# MCXN947_cm33_core0 register map
Vendor: nxp.com; File version: 1.0
CPU: CM33 r2p0, little endian, MPU, FPU, VTOR, 3 interrupt priority bits
Registers are 32-bit, read-write, reset 0x0 unless marked. A register's access mark holds for its fields unless they carry their own. Offsets are from the block's base; [hi:lo] are bit positions; {n}, {i} and the like mark numbered series; 'fields as' and 'values as' point back to an identical list.

## FLEXIO0 — FLEXIO
Base 0x40105000
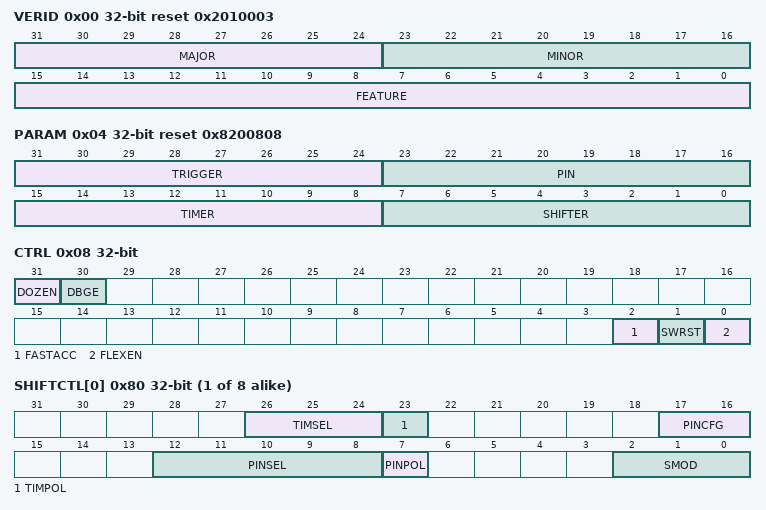
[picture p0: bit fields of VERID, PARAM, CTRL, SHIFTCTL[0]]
0x00 VERID ro reset 0x2010003 — Version ID Register
  [31:24] MAJOR — Major Version Number
  [23:16] MINOR — Minor Version Number
  [15:0] FEATURE — Feature Specification Number
    0=Standard features implemented; 1=state_logic_parallel (Supports state, logic, and parallel modes.); 2=pinctrl (Supports pin control registers.); 3=state_logic_parallel_pinctrl (Supports state, logic, and parallel modes, plus pin control registers.)
0x04 PARAM ro reset 0x8200808 — Parameter Register
  [31:24] TRIGGER — Trigger Number
  [23:16] PIN — Pin Number
  [15:8] TIMER — Timer Number
  [7:0] SHIFTER — Shifter Number
0x08 CTRL — FLEXIO Control Register
  [31] DOZEN — Doze Enable
    0=enable (FLEXIO enabled in Doze modes.); 1=disable (FLEXIO disabled in Doze modes.)
  [30] DBGE — Debug Enable
    0=disable (FLEXIO is disabled in Debug modes.); 1=emable (FLEXIO is enabled in Debug modes.)
  [2] FASTACC — Fast Access
    0=normal (Configures for normal register accesses to FLEXIO); 1=fast (Configures for fast register accesses to FLEXIO)
  [1] SWRST — Software Reset
    0=disable (Software reset is disabled); 1=enable (Software reset is enabled. All FLEXIO registers except the Control Register are reset.)
  [0] FLEXEN — FLEXIO Enable
    0=disable (FLEXIO module is disabled.); 1=enable (FLEXIO module is enabled.)
0x0C PIN ro — Pin State Register
  [31:0] PDI — Pin Data Input
0x10 SHIFTSTAT write-1-clears — Shifter Status Register
  [7:0] SSF write-1-clears — Shifter Status Flag
0x14 SHIFTERR write-1-clears — Shifter Error Register
  [7:0] SEF write-1-clears — Shifter Error Flags
0x18 TIMSTAT write-1-clears — Timer Status Register
  [7:0] TSF write-1-clears — Timer Status Flags
0x20 SHIFTSIEN — Shifter Status Interrupt Enable
  [7:0] SSIE
0x24 SHIFTEIEN — Shifter Error Interrupt Enable
  [7:0] SEIE
0x28 TIMIEN — Timer Interrupt Enable Register
  [7:0] TEIE — Timer Status Interrupt Enable
0x30 SHIFTSDEN — Shifter Status DMA Enable
  [7:0] SSDE
0x38 TIMERSDEN — Timer Status DMA Enable
  [7:0] TSDE
0x40 SHIFTSTATE — Shifter State Register
  [2:0] STATE — Current State Pointer
0x48 TRGSTAT write-1-clears — Trigger Status Register
  [7:0] ETSF write-1-clears — External Trigger Status Flags
0x4C TRIGIEN — External Trigger Interrupt Enable Register
  [7:0] TRIE — External Trigger Interrupt Enable
0x50 PINSTAT write-1-clears — Pin Status Register
  [31:0] PSF write-1-clears — Pin Status Flags
0x54 PINIEN — Pin Interrupt Enable Register
  [31:0] PSIE — Pin Status Interrupt Enable
0x58 PINREN — Pin Rising Edge Enable Register
  [31:0] PRE — Pin Rising Edge
0x5C PINFEN — Pin Falling Edge Enable Register
  [31:0] PFE — Pin Falling Edge
0x60 PINOUTD — Pin Output Data Register
  [31:0] OUTD — Output Data
0x64 PINOUTE — Pin Output Enable Register
  [31:0] OUTE — Output Enable
0x68 PINOUTDIS — Pin Output Disable Register
  [31:0] OUTDIS — Output Disable
0x6C PINOUTCLR — Pin Output Clear Register
  [31:0] OUTCLR — Output Clear
0x70 PINOUTSET — Pin Output Set Register
  [31:0] OUTSET — Output Set
0x74 PINOUTTOG — Pin Output Toggle Register
  [31:0] OUTTOG — Output Toggle
{0x80+4i} SHIFTCTL[{i}] (i=0..7) — Shifter Control N Register
  [26:24] TIMSEL — Timer Select
  [23] TIMPOL — Timer Polarity
    0=posedge (Shift on posedge of shift clock); 1=negedge (Shift on negedge of shift clock)
  [17:16] PINCFG — Shifter Pin Configuration
    0=disable (Shifter pin output disabled); 1=opend_bidirouten (Shifter pin open-drain or bidirectional output enable); 2=bidir_outdata (Shifter pin bidirectional output data); 3=output (Shifter pin output)
  [12:8] PINSEL — Shifter Pin Select
  [7] PINPOL — Shifter Pin Polarity
    0=active_high (Pin is active high); 1=active_low (Pin is active low)
  [2:0] SMOD — Shifter Mode
    0=Disabled; 1=Receive mode. Captures the current shifter content into the SHIFTBUF on expiration of the timer.; 2=Transmit mode. Load SHIFTBUF contents into the shifter on expiration of the timer.; 4=Match Store mode. Shifter data is compared to SHIFTBUF content on expiration of the timer.; 5=Match Continuous mode. Shifter data is continuously compared to SHIFTBUF contents.; 6=State mode. SHIFTBUF contents are used for storing programmable state attributes.; 7=Logic mode. SHIFTBUF contents are used for implementing programmable logic lookup table.
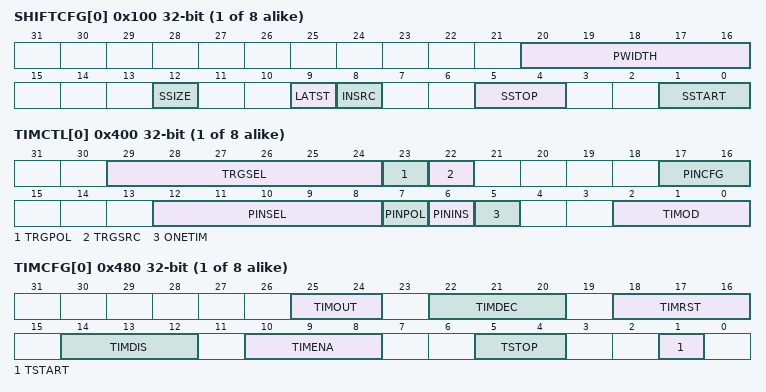
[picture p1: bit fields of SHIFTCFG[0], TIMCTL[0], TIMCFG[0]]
{0x100+4i} SHIFTCFG[{i}] (i=0..7) — Shifter Configuration N Register
  [20:16] PWIDTH — Parallel Width
  [12] SSIZE — Shifter Size
    0=width32 (Shift register is 32-bit.); 1=width24 (Shift register is 24-bit.)
  [9] LATST — Late Store
    0=preshift (Shift register stores the pre-shift register state.); 1=postshift (Shift register stores the post-shift register state.)
  [8] INSRC — Input Source
    0=pin; 1=shifter_nplus1 (Shifter N+1 Output)
  [5:4] SSTOP — Shifter Stop bit
    0=Stop bit disabled for transmitter/receiver/match store; 1=Stop bit disabled for transmitter/receiver/match store. When timer is in stop condition, receiver/match store stores receive data on the configured shift edge.; 2=Transmitter outputs stop bit value 0 on store. If stop bit is not 0, receiver/match store sets error flag. When timer is in stop condition, receiver/match stores also store receive data on the configured shift edge.; 3=Transmitter outputs stop bit value 1 on store. If stop bit is not 1, receiver/match store sets error flag. When timer is in stop condition, receiver/match store also stores receive data on the configured shift edge.
  [1:0] SSTART — Shifter Start Bit
    0=Start bit disabled for transmitter/receiver/match store. Transmitter loads data on enable.; 1=Start bit disabled for transmitter/receiver/match store. Transmitter loads data on first shift.; 2=Transmitter outputs start bit value 0 before loading data on first shift. If start bit is not 0, receiver/match store sets error flag.; 3=Transmitter outputs start bit value 1 before loading data on first shift. If start bit is not 1, receiver/match store sets error flag.
{0x200+4i} SHIFTBUF[{i}] (i=0..7) — Shifter Buffer N Register
  [31:0] SHIFTBUF — Shift Buffer
{0x280+4i} SHIFTBUFBIS[{i}] (i=0..7) — Shifter Buffer N Bit Swapped Register
  [31:0] SHIFTBUFBIS — Shift Buffer
{0x300+4i} SHIFTBUFBYS[{i}] (i=0..7) — Shifter Buffer N Byte Swapped Register
  [31:0] SHIFTBUFBYS — Shift Buffer
{0x380+4i} SHIFTBUFBBS[{i}] (i=0..7) — Shifter Buffer N Bit Byte Swapped Register
  [31:0] SHIFTBUFBBS — Shift Buffer
{0x400+4i} TIMCTL[{i}] (i=0..7) — Timer Control N Register
  [29:24] TRGSEL — Trigger Select
  [23] TRGPOL — Trigger Polarity
    0=active_high (Trigger active high); 1=active_low (Trigger active low)
  [22] TRGSRC — Trigger Source
    0=ext_trig (External trigger selected); 1=Internal trigger selected
  [17:16] PINCFG — Timer Pin Configuration
    0=outdisable (Timer pin output disabled); 1=opend_bidirouten (Timer pin open-drain or bidirectional output enable); 2=bidir_outdata (Timer pin bidirectional output data); 3=output (Timer pin output)
  [12:8] PINSEL — Timer Pin Select
  [7] PINPOL — Timer Pin Polarity
    values as SHIFTCTL[0].PINPOL
  [6] PININS — Timer Pin Input Select
    0=pinsel (Timer pin input and output are selected by PINSEL.); 1=pinselplus1 (Timer pin input is selected by PINSEL+1. Timer pin output remains selected by PINSEL.)
  [5] ONETIM — Timer One Time Operation
    0=not_blocked (The timer enable event is generated as normal.); 1=blocked (The timer enable event is blocked unless timer status flag is clear.)
  [2:0] TIMOD — Timer Mode
    0=disable (Timer disabled.); 1=dual8bit_baud (Dual 8-bit counters baud mode.); 2=dual8bit_pwm_h (Dual 8-bit counters PWM high mode.); 3=Single 16-bit counter mode; 4=single16bit_disable (Single 16-bit counter disable mode.); 5=dual8bit_word (Dual 8-bit counters word mode.); 6=dual8bit_pwm_l (Dual 8-bit counters PWM low mode.); 7=single16bit_in_capture (Single 16-bit input capture mode.)
{0x480+4i} TIMCFG[{i}] (i=0..7) — Timer Configuration N Register
  [25:24] TIMOUT — Timer Output
    0=one (Timer output is logic one when enabled and is not affected by timer reset); 1=zero (Timer output is logic zero when enabled and is not affected by timer reset); 2=one_tmrreset (Timer output is logic one when enabled and on timer reset); 3=zero_tmrreset (Timer output is logic zero when enabled and on timer reset)
  [22:20] TIMDEC — Timer Decrement
    0=flexio_clk_shiftclk_tmr_out (Decrement counter on FLEXIO clock. Shift clock equals timer output.); 1=trig_edge_shiftclk_tmr_out (Decrement counter on trigger input (both edges). Shift clock equals timer output.); 2=pin_edge_shiftclk_tmr_out (Decrement counter on pin input (both edges). Shift clock equals pin input.); 3=trig_edge_shiftclk_trig_in (Decrement counter on trigger input (both edges). Shift clock equals trigger input.); 4=flexio_clk_div16_shiftclk_tmr_out (Decrement counter on FLEXIO clock divided by 16. Shift clock equals timer output.); 5=flexio_clk_div256_shiftclk_tmr_out (Decrement counter on FLEXIO clock divided by 256. Shift clock equals timer output.); 6=pin_rise_shiftclk_pin_in (Decrement counter on pin input (rising edge). Shift clock equals pin input.); 7=trig_rise_shiftclk_trig_in (Decrement counter on trigger input (rising edge). Shift clock equals trigger input.)
  [18:16] TIMRST — Timer Reset
    0=never (Timer never reset); 1=tmr_out_hi (Timer reset on timer output high.); 2=pin_eq_tmr_out (Timer reset on timer pin equal to timer output); 3=trig_eq_tmr_out (Timer reset on timer trigger equal to timer output); 4=pin_rise_edge (Timer reset on timer pin rising edge); 6=trig_rise_edge (Timer reset on trigger rising edge); 7=trig_edge (Timer reset on trigger rising or falling edge)
  [14:12] TIMDIS — Timer Disable
    0=never (Timer never disabled); 1=tmr_nminus1 (Timer disabled on Timer N-1 disable); 2=tmr_cmp (Timer disabled on timer compare (upper 8-bits match and decrement)); 3=tmr_cmp_triglow (Timer disabled on timer compare (upper 8-bits match and decrement) and trigger low); 4=pin_edge (Timer disabled on pin rising or falling edge); 5=pin_edge_trighi (Timer disabled on pin rising or falling edge provided trigger is high); 6=trig_falledge (Timer disabled on trigger falling edge)
  [10:8] TIMENA — Timer Enable
    0=enable (Timer always enabled); 1=tmr_nminus1_en (Timer enabled on Timer N-1 enable); 2=tmr_trighi_en (Timer enabled on Trigger high); 3=tmr_trig_pin_hi_en (Timer enabled on Trigger high and Pin high); 4=tmr_pinrise_en (Timer enabled on Pin rising edge); 5=tmr_pinrise_trighi_en (Timer enabled on Pin rising edge and Trigger high); 6=tmr_trigrise_en (Timer enabled on Trigger rising edge); 7=tmr_trigedge_en (Timer enabled on Trigger rising or falling edge)
  [5:4] TSTOP — Timer Stop Bit
    0=stop_disable (Stop bit disabled); 1=enable_tmrcmp (Stop bit is enabled on timer compare); 2=enable_tmrdisable (Stop bit is enabled on timer disable); 3=enable_tmr_cmp_dis (Stop bit is enabled on timer compare and timer disable)
  [1] TSTART — Timer Start Bit
    0=disable (Start bit disabled); 1=enable (Start bit enabled)
{0x500+4i} TIMCMP[{i}] (i=0..7) — Timer Compare N Register
  [15:0] CMP — Timer Compare Value
{0x680+4i} SHIFTBUFNBS[{i}] (i=0..7) — Shifter Buffer N Nibble Byte Swapped Register
  [31:0] SHIFTBUFNBS — Shift Buffer
{0x700+4i} SHIFTBUFHWS[{i}] (i=0..7) — Shifter Buffer N Halfword Swapped Register
  [31:0] SHIFTBUFHWS — Shift Buffer
{0x780+4i} SHIFTBUFNIS[{i}] (i=0..7) — Shifter Buffer N Nibble Swapped Register
  [31:0] SHIFTBUFNIS — Shift Buffer
{0x800+4i} SHIFTBUFOES[{i}] (i=0..7) — Shifter Buffer N Odd Even Swapped Register
  [31:0] SHIFTBUFOES — Shift Buffer
{0x880+4i} SHIFTBUFEOS[{i}] (i=0..7) — Shifter Buffer N Even Odd Swapped Register
  [31:0] SHIFTBUFEOS — Shift Buffer
{0x900+4i} SHIFTBUFHBS[{i}] (i=0..7) — Shifter Buffer N Halfword Byte Swapped Register
  [31:0] SHIFTBUFHBS — Shift Buffer
